# ESP32S31_RADIO register map
Vendor: Espressif; Series: ESP32-S31; File version: 3.52
Registers are 32-bit, read-write, no defined reset value unless marked. A register's access mark holds for its fields unless they carry their own. Offsets are from the block's base; [hi:lo] are bit positions; {n}, {i} and the like mark numbered series; 'fields as' and 'values as' point back to an identical list.

## BLE_HW_CTE_RING_CONTROL — Direction-finding ring state recovered from complete ESP32-S31 ble_hw_cte.c leaves. Ordinary advertising, scanning and connection link states retain a controller-global disabled-CTE descriptor even when IQ sampling is not requested, so the baseline pointer and ownership fields are part of the minimum standalone BLE controller.
Base 0x2010199C
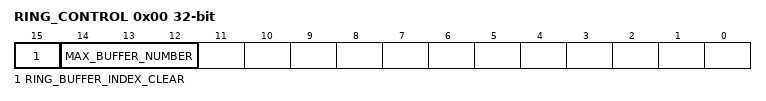
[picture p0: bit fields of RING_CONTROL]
0x00 RING_CONTROL — Project-assigned name. Reset writes the complete word as zero; independent accessors update the ring index and maximum-buffer fields through halfword RMW operations.
  [15] RING_BUFFER_INDEX_CLEAR — Project-assigned name. The named clear accessor sets bit 15. The active level and any hardware self-clear behavior remain unproven.
  [14:12] MAX_BUFFER_NUMBER — Project-assigned name. The setter truncates its argument to three bits and replaces bits 12..14; the getter returns the same field.
{0x4+8i} BUFFER_POINTER{i} (i=0..5) — Project-assigned name. Compressed controller-SRAM address of one CTE sample-ring descriptor. The setter replaces bits 0..19 and preserves the upper twelve bits.
  [19:0] COMPRESSED_DESCRIPTOR_POINTER — Project-assigned name. Low-twenty-bit controller-SRAM pointer reconstructed with the fixed 0x2f prefix and four-byte alignment.
{0x8+8i} BUFFER_STATE{i} (i=0..5) — Project-assigned name. Hardware state paired with one CTE sample-ring descriptor. Only the software-ownership flag is currently assigned.
  [31] SOFTWARE_OWNED — Project-assigned name. The named owner-clear/set leaves respectively clear and set bit 31; the paired query returns that bit.

## BLE_ISO_SCHEDULER_NOTIFY — Narrow late-feature owner for the command written by two complete ISO-path functions. A positional capability is intentional: the observed write strobe is exact, while the undocumented hardware action is not inferred from the software queue context.
Base 0x20101424
0x00 COMMAND wo — Project-assigned name. Both observed ISO-path publications write the complete value one.
  [0] TRIGGER — Project-assigned name. Observed command image is one; hardware self-clear and command meaning remain unknown.

## BT_V3_2_CTE_ANTENNA_MAP — The halfword antenna-map window of the Bluetooth direction-finding block, which the vendor CTE setter stores halfword by halfword. Kept for bit-use coverage: its registers are not 32 bits wide, so no typed owner exists.
Base 0x20102130
{0x0+2i} ANTENNA_MAP_ENTRY{i} (i=0..15) 16-bit wo — Project-assigned name. First sixteen halfword slots of the indexed antenna-map window. The complete setter copies caller-provided halfwords from index zero up to its input count; sixteen slots are the exact finite effects recovered under the current analysis bound, not a claim that the hardware window ends here.
  [15:0] VALUE — Project-assigned name. Complete 16-bit antenna-map element; the encoding remains unknown.

## PHY_NRX_RECOVERED_GAPS — Sparse NRX words absent from the public platform PAC.
Base 0x20107800
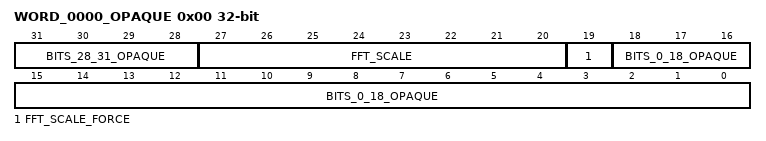
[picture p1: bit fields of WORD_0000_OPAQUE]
0x00 WORD_0000_OPAQUE — Opaque: meaning not established. Complete phy_fft_scale_force read-modify-writes this word.
  [31:28] BITS_28_31_OPAQUE — Opaque: meaning not established. Observed source use; the individual hardware meaning is unknown.
  [27:20] FFT_SCALE — Project-assigned name. FFT scale complete phy_fft_scale_force publishes from its second argument.
  [19] FFT_SCALE_FORCE — Project-assigned name. Force the FFT scale to FFT_SCALE; complete phy_fft_scale_force publishes its first argument here.
  [18:0] BITS_0_18_OPAQUE — Opaque: meaning not established. Observed source use; the individual hardware meaning is unknown.
0x0C WORD_000C_OPAQUE — Opaque: meaning not established. Complete phy_dig_reg_backup saves and restores this word; all field semantics remain unknown.
  [31:0] BITS_0_31_OPAQUE — Opaque: meaning not established. Observed source use; the individual hardware meaning is unknown.
0x30 WORD_0030_OPAQUE — Opaque: meaning not established. Complete phy_spur_reg_write_one_tone reads and replaces this word on three control-flow paths; individual hardware fields remain unnamed.
  fields as WORD_000C_OPAQUE
0x98 WORD_0098_OPAQUE — Opaque: meaning not established. Complete phy_freq_correct read-modify-writes this word; individual fields remain unnamed.
  [9:0] BITS_0_9_OPAQUE — Opaque: meaning not established. Observed source use; the individual hardware meaning is unknown.
0xB8 WORD_00B8_OPAQUE — Opaque: meaning not established. Complete phy_bb_cfo_cfg replaces bits 31:29 with the observed constant pattern while preserving bits 28:0; the hardware field meaning remains unknown.
  [31:29] BITS_29_31_OPAQUE — Opaque: meaning not established.
0x104 WORD_0104_OPAQUE — Opaque: meaning not established. Complete phy_chan_filt_set read-modify-writes this word and complete phy_dig_reg_backup saves/restores it.
  fields as WORD_000C_OPAQUE
